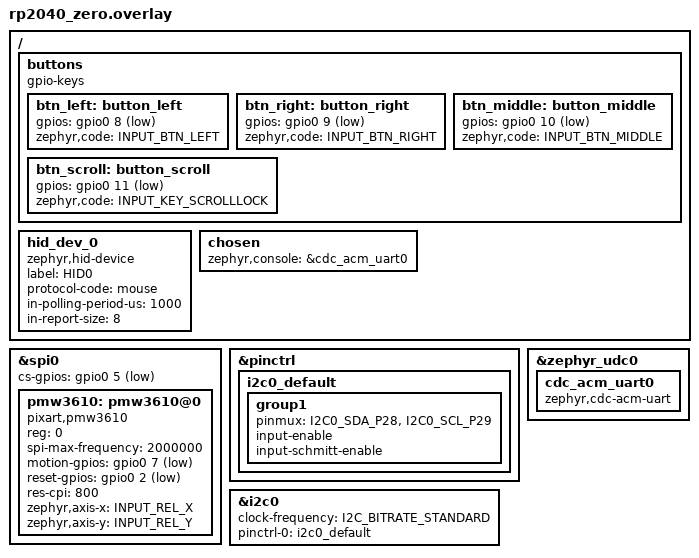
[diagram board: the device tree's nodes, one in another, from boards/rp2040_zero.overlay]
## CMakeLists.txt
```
cmake_minimum_required(VERSION 3.20.0)

find_package(Zephyr REQUIRED HINTS $ENV{ZEPHYR_BASE})
project(trackball_fw C)

target_sources(app PRIVATE
	src/main.c
	src/usb.c
	src/i2c_target.c
)
```

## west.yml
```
# Manifest west de l'application (topologie T2 : l'application est le dépôt manifeste).
# `west update` récupère Zephyr (le driver PMW3610 est natif à l'application).
manifest:
  remotes:
    - name: zephyrproject-rtos
      url-base: https://github.com/zephyrproject-rtos

  projects:
    # Zephyr + ses modules (HAL RP2040, etc.) tirés via import.
    # Figé sur la dernière version stable (v4.4.0, avril 2026).
    - name: zephyr
      remote: zephyrproject-rtos
      revision: v4.4.0
      import: true

    # Le driver PMW3610 est désormais natif (software/drivers/pmw3610.c) :
    # plus aucun module hors-arbre ni dépendance ZMK.

  self:
    # Doit correspondre au nom du dossier de l'application dans l'espace de
    # travail (west init -l software).
    path: software
```

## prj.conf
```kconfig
# --- Configuration Zephyr : trackball RP2040-Zero + PMW3610 (souris HID USB) ---

# Bus et E/S nécessaires au capteur
CONFIG_GPIO=y
CONFIG_SPI=y

# Sous-système input : le driver PMW3610 publie des évènements INPUT_EV_REL
CONFIG_INPUT=y

# --- USB : nouveau stack (device_next) ---
# Le stack legacy (CONFIG_USB_DEVICE_STACK) est déprécié et supprimé en Zephyr 4.5.
CONFIG_USB_DEVICE_STACK_NEXT=y
CONFIG_USBD_HID_SUPPORT=y       # classe HID (souris)
CONFIG_USBD_CDC_ACM_CLASS=y     # classe CDC-ACM (console de debug)

# Numéro de série USB dérivé de l'identifiant unique du RP2040
CONFIG_HWINFO=y

# Journalisation sur la console USB CDC-ACM (voir chosen dans l'overlay)
CONFIG_LOG=y
CONFIG_LOG_DEFAULT_LEVEL=3
CONFIG_CONSOLE=y
CONFIG_UART_CONSOLE=y
CONFIG_UART_LINE_CTRL=y

# Réduit le bruit du stack USB (ex. requêtes DEVICE_QUALIFIER refusées, normales
# pour un périphérique full-speed) pour garder une console lisible.
CONFIG_USBD_LOG_LEVEL_WRN=y
CONFIG_USBD_HID_LOG_LEVEL_WRN=y
CONFIG_UDC_DRIVER_LOG_LEVEL_WRN=y

# --- Driver PMW3610 ---
# Driver fourni en amont par Zephyr (drivers/input, compatible "pixart,pmw3610").
# Auto-activé dès que le noeud existe dans le devicetree ; explicite ici.
CONFIG_INPUT_PMW3610=y

# --- Boutons (gpio-keys) ---
CONFIG_INPUT_GPIO_KEYS=y

# --- Sortie I2C target (trackball comme module lu par un hote) ---
CONFIG_I2C=y
CONFIG_I2C_TARGET=y
```

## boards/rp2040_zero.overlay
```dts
/*
 * Overlay carte : RP2040-Zero + PMW3610 (souris HID USB)
 * ------------------------------------------------------
 * Reprend le pinctrl `spi0_default` fourni par la carte (rp2040_zero-pinctrl.dtsi) :
 *     SCK          = GP6   (SPI0_SCK_P6)
 *     MOSI (TX)    = GP3   (SPI0_TX_P3)
 *     MISO (RX)    = GP4   (SPI0_RX_P4)
 *
 * Le PMW3610 est un capteur SPI 3 fils HALF-DUPLEX (une seule broche de donnees
 * bidirectionnelle SDIO). Le SPI du RP2040 est MATERIEL et pilote MOSI en
 * permanence (push-pull) : relier GP3 (MOSI) directement a SDIO cree une
 * contention de bus en lecture (product id lu = 0x00/0xFF -> self-test KO).
 * Cablage correct :
 *   - GP4 (MISO) directement sur SDIO ;
 *   - GP3 (MOSI) sur SDIO via une resistance serie ~1k (le capteur l'emporte
 *     en lecture, MOSI ecrit a travers la resistance).
 *
 * Lignes de controle (GPIO) choisies sur des broches libres du RP2040-Zero :
 *     NCS    = GP5   (chip select, actif bas)
 *     MOTION = GP7   (interruption capteur, actif bas, pull-up)
 *     NRESET = GP2   (reset capteur, actif bas ; sequence geree par le driver)
 */

#include <zephyr/dt-bindings/gpio/gpio.h>
#include <zephyr/dt-bindings/input/input-event-codes.h>
#include <zephyr/dt-bindings/pinctrl/rpi-pico-rp2040-pinctrl.h>
#include <zephyr/dt-bindings/i2c/i2c.h>

&spi0 {
	status = "okay";
	cs-gpios = <&gpio0 5 GPIO_ACTIVE_LOW>;

	/* Driver PMW3610 fourni en amont par Zephyr (drivers/input). */
	pmw3610: pmw3610@0 {
		compatible = "pixart,pmw3610";
		reg = <0>;
		spi-max-frequency = <2000000>;   /* PMW3610 : SCLK <= 2 MHz */
		motion-gpios = <&gpio0 7 (GPIO_ACTIVE_LOW | GPIO_PULL_UP)>;
		reset-gpios = <&gpio0 2 GPIO_ACTIVE_LOW>;  /* NRESET, actif bas */
		res-cpi = <800>;                 /* resolution ; a ajuster */
		zephyr,axis-x = <INPUT_REL_X>;
		zephyr,axis-y = <INPUT_REL_Y>;

		/* Orientation (a regler une fois la carte montee) :
		 * invert-x;
		 * invert-y;
		 */
	};
};

/*
 * Boutons de la souris (gpio-keys). Actifs bas avec pull-up interne : une entree
 * non connectee est lue au niveau inactif (bouton relache) -> aucun clic fantome
 * si le poussoir n'est pas cable. Broches libres du RP2040-Zero.
 */
/ {
	buttons {
		compatible = "gpio-keys";

		btn_left: button_left {
			gpios = <&gpio0 8 (GPIO_ACTIVE_LOW | GPIO_PULL_UP)>;
			zephyr,code = <INPUT_BTN_LEFT>;
		};
		btn_right: button_right {
			gpios = <&gpio0 9 (GPIO_ACTIVE_LOW | GPIO_PULL_UP)>;
			zephyr,code = <INPUT_BTN_RIGHT>;
		};
		btn_middle: button_middle {
			gpios = <&gpio0 10 (GPIO_ACTIVE_LOW | GPIO_PULL_UP)>;
			zephyr,code = <INPUT_BTN_MIDDLE>;
		};
		/* Bouton de bascule du mode molette (non transmis a l'hote). */
		btn_scroll: button_scroll {
			gpios = <&gpio0 11 (GPIO_ACTIVE_LOW | GPIO_PULL_UP)>;
			zephyr,code = <INPUT_KEY_SCROLLLOCK>;
		};
	};
};

/* Souris HID (nouveau stack USB device_next) */
/ {
	hid_dev_0: hid_dev_0 {
		compatible = "zephyr,hid-device";
		label = "HID0";
		protocol-code = "mouse";         /* souris boot-capable (BIOS/UEFI) */
		in-polling-period-us = <1000>;   /* 1 kHz */
		in-report-size = <8>;
	};
};

/*
 * Sortie I2C target : le trackball expose son pointage a un controleur hote.
 * I2C0 sur GP28 (SDA) / GP29 (SCL). Pull-ups externes requis (~4.7k vers 3V3),
 * en general cote hote. L'adresse target est fixee au runtime (voir i2c_target.c).
 */
&pinctrl {
	i2c0_default: i2c0_default {
		group1 {
			pinmux = <I2C0_SDA_P28>, <I2C0_SCL_P29>;
			input-enable;
			input-schmitt-enable;
		};
	};
};

&i2c0 {
	status = "okay";
	clock-frequency = <I2C_BITRATE_STANDARD>;   /* 100 kHz */
	pinctrl-0 = <&i2c0_default>;
	pinctrl-names = "default";
};

/* Console de debug sur USB CDC-ACM (pas d'UART cablee en facade) */
&zephyr_udc0 {
	cdc_acm_uart0: cdc_acm_uart0 {
		compatible = "zephyr,cdc-acm-uart";
	};
};

/ {
	chosen {
		zephyr,console = &cdc_acm_uart0;
	};
};
```

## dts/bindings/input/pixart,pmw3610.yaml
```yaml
# Copyright (c) 2026
# SPDX-License-Identifier: Apache-2.0

description: |
  PixArt PMW3610 low-power optical mouse/trackball sensor.

  Le capteur communique en SPI 3 fils (une broche de données SDIO
  bidirectionnelle) : sur un contrôleur SPI full-duplex, relier MOSI et MISO
  ensemble vers SDIO. Le driver publie le déplacement dans le sous-système
  input sous forme d'évènements INPUT_REL_X / INPUT_REL_Y.

compatible: "pixart,pmw3610"

include: spi-device.yaml

properties:
  irq-gpios:
    type: phandle-array
    required: true
    description: |
      Ligne d'interruption MOTION du capteur (active à l'état bas).

  cpi:
    type: int
    default: 800
    description: |
      Résolution en counts par pouce. Plage 200 à 3200, pas de 200.

  swap-xy:
    type: boolean
    description: Échange les axes X et Y.

  invert-x:
    type: boolean
    description: Inverse le signe de l'axe X.

  invert-y:
    type: boolean
    description: Inverse le signe de l'axe Y.
```

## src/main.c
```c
/*
 * Trackball RP2040-Zero + PMW3610 — souris HID USB (Zephyr, stack device_next)
 *
 * Le driver PMW3610 publie le deplacement de la bille dans le sous-systeme `input`
 * (INPUT_REL_X / INPUT_REL_Y) et les boutons (gpio-keys) publient INPUT_BTN_*. On
 * fusionne le tout en rapports de souris HID (boutons, X, Y, molette) transmis a
 * l'hote par l'USB. Un bouton dedie bascule un mode molette (toggle) : l'axe Y du
 * capteur alimente alors la molette au lieu du deplacement vertical.
 */

#include "usb.h"
#include "i2c_target.h"

#include <zephyr/kernel.h>
#include <zephyr/device.h>
#include <zephyr/input/input.h>
#include <zephyr/sys/util.h>
#include <zephyr/usb/usbd.h>
#include <zephyr/usb/class/hid.h>
#include <zephyr/usb/class/usbd_hid.h>
#include <zephyr/logging/log.h>

LOG_MODULE_REGISTER(main, LOG_LEVEL_INF);

/* Descripteur de rapport : souris a 3 boutons (gauche/droit/milieu) + X/Y/molette
 * relatifs. L'argument de la macro est le NOMBRE de boutons declares : il doit
 * valoir 3 pour que le bouton milieu (bit 2) soit vu par l'hote. */
static const uint8_t hid_report_desc[] = HID_MOUSE_REPORT_DESC(3);

enum mouse_report_idx {
	MOUSE_BTN_REPORT_IDX = 0,
	MOUSE_X_REPORT_IDX = 1,
	MOUSE_Y_REPORT_IDX = 2,
	MOUSE_WHEEL_REPORT_IDX = 3,
	MOUSE_REPORT_COUNT = 4,
};

/* File des rapports prets a emettre (producteur : input_cb ; conso : main). */
K_MSGQ_DEFINE(mouse_msgq, MOUSE_REPORT_COUNT, 8, 1);

static const struct device *hid_dev;
static bool mouse_ready;

/* Protocole HID courant (piloté par l'hôte via SET_PROTOCOL).
 * En mode boot (BIOS/UEFI), le rapport souris est figé à 3 octets
 * (boutons, X, Y) ; en mode report, on émet aussi la molette (4 octets).
 * Les 3 premiers octets de notre rapport correspondent déjà au format boot. */
static volatile uint8_t hid_protocol = HID_PROTOCOL_REPORT;
#define MOUSE_BOOT_REPORT_COUNT 3

/* Nombre de counts capteur par cran de molette en mode scroll. */
#define SCROLL_DIV 20

/* Etat persistant : boutons pressés (bits) et mode molette (bascule). */
static uint8_t mouse_buttons;
static bool scroll_mode;
static int32_t scroll_accum;

/* Borne un delta au domaine signe 8 bits du rapport HID. */
static inline uint8_t clamp_delta(int32_t v)
{
	if (v > 127) {
		v = 127;
	} else if (v < -127) {
		v = -127;
	}
	return (uint8_t)(int8_t)v;
}

/* Callback du sous-systeme input : recoit les evenements du capteur ET des
 * boutons (gpio-keys), les fusionne dans un rapport souris emis a la cloture
 * du lot (drapeau sync). */
static void input_cb(struct input_event *evt, void *user_data)
{
	static uint8_t report[MOUSE_REPORT_COUNT];

	ARG_UNUSED(user_data);

	switch (evt->code) {
	case INPUT_BTN_LEFT:
		WRITE_BIT(mouse_buttons, 0, evt->value);
		app_i2c_target_feed(0, 0, mouse_buttons);
		break;
	case INPUT_BTN_RIGHT:
		WRITE_BIT(mouse_buttons, 1, evt->value);
		app_i2c_target_feed(0, 0, mouse_buttons);
		break;
	case INPUT_BTN_MIDDLE:
		WRITE_BIT(mouse_buttons, 2, evt->value);
		app_i2c_target_feed(0, 0, mouse_buttons);
		break;
	case INPUT_KEY_SCROLLLOCK:
		/* Bascule le mode molette sur l'appui ; non transmis a l'hote. */
		if (evt->value) {
			scroll_mode = !scroll_mode;
			scroll_accum = 0;
			LOG_INF("Mode molette : %s", scroll_mode ? "actif" : "inactif");
		}
		return;
	case INPUT_REL_X:
		/* L'I2C recoit toujours le mouvement brut (independant du mode molette). */
		app_i2c_target_feed(evt->value, 0, mouse_buttons);
		/* En mode molette, l'axe X est ignore (pan horizontal non gere). */
		if (!scroll_mode) {
			report[MOUSE_X_REPORT_IDX] = clamp_delta(evt->value);
		}
		break;
	case INPUT_REL_Y:
		app_i2c_target_feed(0, evt->value, mouse_buttons);
		if (scroll_mode) {
			/* Accumulation puis conversion en crans de molette. */
			scroll_accum += evt->value;
			int32_t ticks = scroll_accum / SCROLL_DIV;

			if (ticks != 0) {
				scroll_accum -= ticks * SCROLL_DIV;
				report[MOUSE_WHEEL_REPORT_IDX] = clamp_delta(-ticks);
			}
		} else {
			report[MOUSE_Y_REPORT_IDX] = clamp_delta(evt->value);
		}
		break;
	default:
		return;
	}

	report[MOUSE_BTN_REPORT_IDX] = mouse_buttons;

	if (!evt->sync) {
		return;   /* lot incomplet : on attend le dernier evenement */
	}

	if (k_msgq_put(&mouse_msgq, report, K_NO_WAIT) != 0) {
		LOG_WRN("File de rapports pleine, evenement perdu");
	}

	report[MOUSE_X_REPORT_IDX] = 0U;
	report[MOUSE_Y_REPORT_IDX] = 0U;
	report[MOUSE_WHEEL_REPORT_IDX] = 0U;
}
INPUT_CALLBACK_DEFINE(NULL, input_cb, NULL);

static void mouse_iface_ready(const struct device *dev, const bool ready)
{
	LOG_INF("Interface HID %s : %s", dev->name, ready ? "prete" : "non prete");
	mouse_ready = ready;
}

static int mouse_get_report(const struct device *dev, const uint8_t type,
			    const uint8_t id, const uint16_t len, uint8_t *const buf)
{
	ARG_UNUSED(dev);
	ARG_UNUSED(type);
	ARG_UNUSED(id);
	ARG_UNUSED(len);
	ARG_UNUSED(buf);
	return 0;
}

static void mouse_set_protocol(const struct device *dev, const uint8_t proto)
{
	ARG_UNUSED(dev);
	hid_protocol = proto;
	LOG_INF("Protocole HID : %s", proto == HID_PROTOCOL_BOOT ? "boot" : "report");
}

static struct hid_device_ops mouse_ops = {
	.iface_ready = mouse_iface_ready,
	.get_report = mouse_get_report,
	.set_protocol = mouse_set_protocol,
};

int main(void)
{
	const struct device *const sensor = DEVICE_DT_GET(DT_NODELABEL(pmw3610));
	struct usbd_context *usbd;
	int ret;

	/* IMPORTANT : l'enumeration USB (souris + console serie) NE DOIT PAS
	 * dependre du capteur. Si le PMW3610 n'est pas cable/repond pas, son init
	 * echoue et device_is_ready(sensor) est faux : on continue quand meme pour
	 * que la carte enumere et que la console reste accessible pour diagnostiquer. */

	hid_dev = DEVICE_DT_GET_ONE(zephyr_hid_device);
	if (device_is_ready(hid_dev)) {
		ret = hid_device_register(hid_dev, hid_report_desc,
					  sizeof(hid_report_desc), &mouse_ops);
		if (ret != 0) {
			LOG_ERR("Enregistrement du peripherique HID (%d)", ret);
		}
	} else {
		LOG_ERR("Peripherique HID non pret");
	}

	usbd = app_usbd_init();
	if (usbd == NULL) {
		LOG_ERR("Initialisation USB echouee");
		return -ENODEV;
	}

	ret = usbd_enable(usbd);
	if (ret != 0) {
		LOG_ERR("usbd_enable (%d)", ret);
		return ret;
	}

	LOG_INF("USB actif : souris HID + console CDC");

	if (device_is_ready(sensor)) {
		LOG_INF("Capteur PMW3610 pret");
	} else {
		LOG_WRN("Capteur PMW3610 NON pret : souris sans mouvement "
			"(verifier cablage SPI / pont MOSI-MISO)");
	}

	/* Sortie I2C target (non bloquante : absente si le bus n'est pas pret). */
	(void)app_i2c_target_init();

	while (true) {
		UDC_STATIC_BUF_DEFINE(report, MOUSE_REPORT_COUNT);

		k_msgq_get(&mouse_msgq, &report, K_FOREVER);

		if (!mouse_ready) {
			continue;   /* hote non connecte : on ignore le mouvement */
		}

		/* Mode boot : rapport de 3 octets (boutons, X, Y) sans molette. */
		const uint8_t len = (hid_protocol == HID_PROTOCOL_BOOT)
					    ? MOUSE_BOOT_REPORT_COUNT
					    : MOUSE_REPORT_COUNT;

		ret = hid_device_submit_report(hid_dev, len, report);
		if (ret != 0) {
			LOG_ERR("Envoi du rapport HID (%d)", ret);
		}
	}

	return 0;
}
```

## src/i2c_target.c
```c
/*
 * Sortie I2C target du trackball.
 *
 * SPDX-License-Identifier: Apache-2.0
 *
 * Le RP2040 s'enregistre comme peripherique I2C (mode target, driver DesignWare
 * `i2c_dw` via CONFIG_I2C_TARGET) sur le bus i2c0 (GP28=SDA, GP29=SCL). Un
 * controleur hote lit le pointage via une petite carte de registres a
 * auto-incrementation :
 *
 *   0x00  WHO_AM_I  constante d'identification (0x3C)
 *   0x01  BUTTONS   bit0 gauche, bit1 droit, bit2 milieu (niveau)
 *   0x02  DX        delta X (int8), read-to-clear
 *   0x03  DY        delta Y (int8), read-to-clear
 *
 * Protocole : l'hote ecrit 1 octet (index de registre de depart) puis lit N
 * octets (l'index s'auto-incremente). Les deltas DX/DY sont bornes a int8 et
 * decrementes de ce qui est renvoye (le reliquat est conserve pour la lecture
 * suivante : aucune perte si |delta| depasse 127).
 *
 * Les callbacks target s'executent en contexte ISR ; l'accumulation (feed) se
 * fait dans le thread input et protege sa lecture-modification par irq_lock().
 */

#include "i2c_target.h"

#include <zephyr/device.h>
#include <zephyr/drivers/i2c.h>
#include <zephyr/kernel.h>
#include <zephyr/logging/log.h>

LOG_MODULE_REGISTER(app_i2c, LOG_LEVEL_INF);

#define I2C_TARGET_NODE DT_NODELABEL(i2c0)

/* Adresse 7 bits du target (a adapter au besoin cote hote). */
#define I2C_TARGET_ADDRESS 0x54

/* Carte de registres */
#define REG_WHO_AM_I 0x00
#define REG_BUTTONS  0x01
#define REG_DX       0x02
#define REG_DY       0x03
#define WHO_AM_I_VALUE 0x3C

/* Etat partagé thread input <-> ISR I2C. */
static int32_t acc_dx;
static int32_t acc_dy;
static uint8_t cur_buttons;

/* Index de registre courant de la transaction I2C en cours. */
static uint8_t reg_ptr;

/* Prend jusqu'a +/-127 counts de l'accumulateur et renvoie la valeur int8
 * correspondante (le reliquat reste pour la prochaine lecture). Contexte ISR. */
static int8_t take_delta(int32_t *acc)
{
	int32_t v = *acc;

	if (v > 127) {
		v = 127;
	} else if (v < -127) {
		v = -127;
	}
	*acc -= v;
	return (int8_t)v;
}

/* Lit l'octet du registre et avance l'index (contexte ISR). */
static uint8_t reg_read(void)
{
	uint8_t val;

	switch (reg_ptr) {
	case REG_WHO_AM_I:
		val = WHO_AM_I_VALUE;
		break;
	case REG_BUTTONS:
		val = cur_buttons;
		break;
	case REG_DX:
		val = (uint8_t)take_delta(&acc_dx);
		break;
	case REG_DY:
		val = (uint8_t)take_delta(&acc_dy);
		break;
	default:
		val = 0x00;
		break;
	}

	reg_ptr++;
	return val;
}

static int target_write_requested(struct i2c_target_config *config)
{
	ARG_UNUSED(config);
	return 0;
}

/* Premier (et unique) octet ecrit par l'hote = index de registre de depart. */
static int target_write_received(struct i2c_target_config *config, uint8_t val)
{
	ARG_UNUSED(config);
	reg_ptr = val;
	return 0;
}

static int target_read_requested(struct i2c_target_config *config, uint8_t *val)
{
	ARG_UNUSED(config);
	*val = reg_read();
	return 0;
}

static int target_read_processed(struct i2c_target_config *config, uint8_t *val)
{
	ARG_UNUSED(config);
	*val = reg_read();
	return 0;
}

static int target_stop(struct i2c_target_config *config)
{
	ARG_UNUSED(config);
	return 0;
}

static struct i2c_target_callbacks target_cbs = {
	.write_requested = target_write_requested,
	.write_received = target_write_received,
	.read_requested = target_read_requested,
	.read_processed = target_read_processed,
	.stop = target_stop,
};

static struct i2c_target_config target_cfg = {
	.address = I2C_TARGET_ADDRESS,
	.callbacks = &target_cbs,
};

void app_i2c_target_feed(int dx, int dy, uint8_t buttons)
{
	unsigned int key = irq_lock();

	acc_dx += dx;
	acc_dy += dy;
	cur_buttons = buttons;

	irq_unlock(key);
}

int app_i2c_target_init(void)
{
	const struct device *const dev = DEVICE_DT_GET(I2C_TARGET_NODE);
	int ret;

	if (!device_is_ready(dev)) {
		LOG_ERR("Bus I2C0 non pret");
		return -ENODEV;
	}

	ret = i2c_target_register(dev, &target_cfg);
	if (ret != 0) {
		LOG_ERR("Enregistrement I2C target echoue (%d)", ret);
		return ret;
	}

	LOG_INF("Sortie I2C target active @0x%02x (GP28=SDA, GP29=SCL)",
		target_cfg.address);
	return 0;
}
```

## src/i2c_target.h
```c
/*
 * Sortie I2C target : expose le pointage du trackball a un controleur hote.
 */
#ifndef TRACKBALL_I2C_TARGET_H
#define TRACKBALL_I2C_TARGET_H

#include <stdint.h>

/*
 * Enregistre le trackball comme peripherique I2C target (non bloquant).
 * Renvoie 0 si l'enregistrement a reussi, un code d'erreur sinon (dans ce cas
 * la sortie I2C est simplement absente, le reste du firmware continue).
 */
int app_i2c_target_init(void);

/*
 * Accumule le mouvement et met a jour l'etat des boutons, pour lecture par
 * l'hote I2C. Appelee depuis le callback input (thread input).
 *   dx, dy  : deltas bruts du capteur (indépendants du mode molette USB)
 *   buttons : bit0 gauche, bit1 droit, bit2 milieu
 */
void app_i2c_target_feed(int dx, int dy, uint8_t buttons);

#endif /* TRACKBALL_I2C_TARGET_H */
```

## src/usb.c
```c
/*
 * Contexte USB device (nouveau stack Zephyr, device_next).
 *
 * Adapté du code de référence des samples Zephyr
 * (samples/subsys/usb/common/sample_usbd_init.c), simplifié pour un seul
 * périphérique pleine vitesse (le RP2040 n'expose que du Full-Speed) et sans
 * dépendance aux options Kconfig.sample_usbd.
 */

#include "usb.h"

#include <zephyr/device.h>
#include <zephyr/usb/usbd.h>
#include <zephyr/logging/log.h>

LOG_MODULE_REGISTER(app_usb, LOG_LEVEL_INF);

/*
 * VID/PID de TEST (pid.codes 0x1209 / 0x0001) : à REMPLACER par une paire
 * propre au projet avant toute distribution. Ne jamais réutiliser le VID des
 * samples Zephyr en dehors des samples.
 */
#define APP_USBD_VID       0x1209
#define APP_USBD_PID       0x0001
#define APP_USBD_MAX_POWER 250   /* 500 mA */

USBD_DEVICE_DEFINE(app_usbd,
		   DEVICE_DT_GET(DT_NODELABEL(zephyr_udc0)),
		   APP_USBD_VID, APP_USBD_PID);

USBD_DESC_LANG_DEFINE(app_lang);
USBD_DESC_MANUFACTURER_DEFINE(app_mfr, "Trackball DIY");
USBD_DESC_PRODUCT_DEFINE(app_product, "Trackball RP2040-Zero");
IF_ENABLED(CONFIG_HWINFO, (USBD_DESC_SERIAL_NUMBER_DEFINE(app_sn)));

USBD_DESC_CONFIG_DEFINE(fs_cfg_desc, "FS Configuration");

/* Bus-powered ; une seule configuration pleine vitesse. */
USBD_CONFIGURATION_DEFINE(app_fs_config, 0, APP_USBD_MAX_POWER, &fs_cfg_desc);

/*
 * Périphérique composite : quand la classe CDC-ACM est présente, les
 * interfaces sont regroupées par un IAD, ce qui impose le triple de code
 * "Miscellaneous / Common Class / IAD".
 */
static void fix_code_triple(struct usbd_context *ctx, const enum usbd_speed speed)
{
	if (IS_ENABLED(CONFIG_USBD_CDC_ACM_CLASS)) {
		usbd_device_set_code_triple(ctx, speed,
					    USB_BCC_MISCELLANEOUS, 0x02, 0x01);
	} else {
		usbd_device_set_code_triple(ctx, speed, 0, 0, 0);
	}
}

struct usbd_context *app_usbd_init(void)
{
	int err;

	err = usbd_add_descriptor(&app_usbd, &app_lang);
	if (err) {
		LOG_ERR("Descripteur langue (%d)", err);
		return NULL;
	}

	err = usbd_add_descriptor(&app_usbd, &app_mfr);
	if (err) {
		LOG_ERR("Descripteur fabricant (%d)", err);
		return NULL;
	}

	err = usbd_add_descriptor(&app_usbd, &app_product);
	if (err) {
		LOG_ERR("Descripteur produit (%d)", err);
		return NULL;
	}

	IF_ENABLED(CONFIG_HWINFO, (
		err = usbd_add_descriptor(&app_usbd, &app_sn);
		if (err) {
			LOG_ERR("Descripteur numero de serie (%d)", err);
			return NULL;
		}
	))

	err = usbd_add_configuration(&app_usbd, USBD_SPEED_FS, &app_fs_config);
	if (err) {
		LOG_ERR("Ajout de la configuration Full-Speed (%d)", err);
		return NULL;
	}

	err = usbd_register_all_classes(&app_usbd, USBD_SPEED_FS, 1, NULL);
	if (err) {
		LOG_ERR("Enregistrement des classes (%d)", err);
		return NULL;
	}

	fix_code_triple(&app_usbd, USBD_SPEED_FS);
	usbd_self_powered(&app_usbd, false);

	err = usbd_init(&app_usbd);
	if (err) {
		LOG_ERR("usbd_init (%d)", err);
		return NULL;
	}

	return &app_usbd;
}
```

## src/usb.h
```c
/*
 * Contexte USB device (nouveau stack Zephyr, device_next).
 */
#ifndef TRACKBALL_USB_H
#define TRACKBALL_USB_H

#include <zephyr/usb/usbd.h>

/*
 * Configure et initialise le peripherique USB (descripteurs, configuration
 * pleine vitesse, enregistrement des classes disponibles : HID + CDC-ACM).
 * Renvoie le contexte pret a etre active par usbd_enable(), ou NULL en cas
 * d'erreur.
 */
struct usbd_context *app_usbd_init(void);

#endif /* TRACKBALL_USB_H */
```
